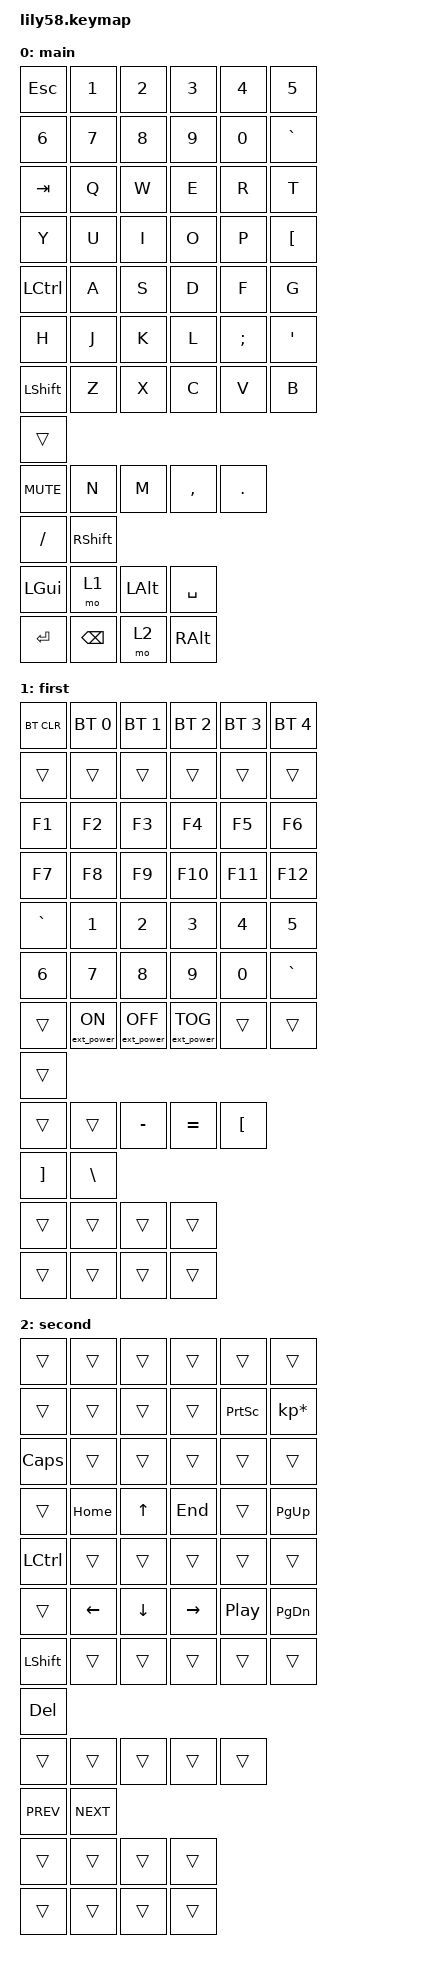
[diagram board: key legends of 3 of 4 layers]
/*
 * Copyright (c) 2020 The ZMK Contributors
 *
 * SPDX-License-Identifier: MIT
 */

#include <behaviors.dtsi>
#include <dt-bindings/zmk/keys.h>
#include <dt-bindings/zmk/bt.h>
#include <dt-bindings/zmk/ext_power.h>
#include <dt-bindings/zmk/rgb.h>

/ {
    conditional_layers {
        compatible = "zmk,conditional-layers";

        adjust_layer {
            if-layers = <1 2>;
            then-layer = <3>;
        };
    };

    keymap {
        compatible = "zmk,keymap";

        /*
         * Layer 0 — твой скрин 0
         */
        default_layer {
			display-name = "main";

            bindings = <
                &kp ESC       &kp N1      &kp N2      &kp N3      &kp N4      &kp N5
                &kp N6        &kp N7      &kp N8      &kp N9      &kp N0      &kp GRAVE

                &kp TAB       &kp Q       &kp W       &kp E       &kp R       &kp T
                &kp Y         &kp U       &kp I       &kp O       &kp P       &kp LBKT

                &kp LCTRL     &kp A       &kp S       &kp D       &kp F       &kp G
                &kp H         &kp J       &kp K       &kp L       &kp SEMI     &kp SQT

                &kp LSHFT     &kp Z       &kp X       &kp C       &kp V       &kp B
                &trans
                &kp C_MUTE    &kp N       &kp M       &kp COMMA    &kp DOT
                &kp FSLH      &kp RSHFT

                &kp LGUI      &mo 1       &kp LALT    &kp SPACE
                &kp RET       &kp BSPC    &mo 2       &kp RALT
            >;

            sensor-bindings = <
                &inc_dec_kp C_VOL_UP C_VOL_DN
                &inc_dec_kp C_VOL_UP C_VOL_DN
            >;
        };

        /*
         * Layer 1 — твой скрин 1
         */
        lower_layer {
			display-name = "first";

            bindings = <
                &bt BT_CLR       &bt BT_SEL 0     &bt BT_SEL 1     &bt BT_SEL 2     &bt BT_SEL 3     &bt BT_SEL 4
                &trans           &trans           &trans           &trans           &trans           &trans

                &kp F1           &kp F2            &kp F3            &kp F4            &kp F5            &kp F6
                &kp F7           &kp F8            &kp F9            &kp F10           &kp F11           &kp F12

                &kp GRAVE        &kp N1            &kp N2            &kp N3            &kp N4            &kp N5
                &kp N6           &kp N7            &kp N8            &kp N9            &kp N0            &kp GRAVE

                &trans           &ext_power EP_ON  &ext_power EP_OFF  &ext_power EP_TOG  &trans           &trans
                &trans           &trans            &trans             &kp MINUS         &kp EQUAL        &kp LBKT
                &kp RBKT         &kp BSLH

                &trans           &trans           &trans           &trans
                &trans           &trans           &trans           &trans
            >;

            sensor-bindings = <
                &inc_dec_kp C_VOL_UP C_VOL_DN
                &inc_dec_kp C_VOL_UP C_VOL_DN
            >;
        };

        /*
         * Layer 2 — твой скрин 3
         */
        raise_layer {
			display-name = "second";

			bindings = <
				&trans        &trans        &trans        &trans        &trans        &trans
				&trans        &trans        &trans        &trans        &kp PSCRN      &kp KP_MULTIPLY

				&kp CAPS      &trans        &trans        &trans        &trans        &trans
				&trans        &kp HOME      &kp UP        &kp END       &trans        &kp PG_UP

				&kp LCTRL     &trans        &trans        &trans        &trans        &trans
				&trans        &kp LEFT      &kp DOWN      &kp RIGHT      &kp C_PP      &kp PG_DN

				&kp LSHFT     &trans        &trans        &trans        &trans        &trans
				&kp DEL       &trans        &trans        &trans        &trans        &trans        &kp C_PREV    &kp C_NEXT

				&trans        &trans        &trans        &trans
				&trans        &trans        &trans        &trans
			>;

			sensor-bindings = <
				&inc_dec_kp C_VOL_UP C_VOL_DN
				&inc_dec_kp C_VOL_UP C_VOL_DN
			>;
		};
		
        /*
         * Layer 3 — ОРИГИНАЛЬНЫЙ ADJUST
         */
        adjust_layer {
			display-name = "adj";

            bindings = <
                &bt BT_CLR        &bt BT_SEL 0    &bt BT_SEL 1    &bt BT_SEL 2    &bt BT_SEL 3    &bt BT_SEL 4
                &trans            &trans          &trans          &trans          &trans          &trans

                &ext_power EP_TOG &rgb_ug RGB_HUD &rgb_ug RGB_HUI &rgb_ug RGB_SAD &rgb_ug RGB_SAI &rgb_ug RGB_EFF
                &trans            &trans          &trans          &trans          &trans          &trans

                &trans            &rgb_ug RGB_BRD &rgb_ug RGB_BRI &trans          &trans          &trans
                &trans            &trans          &trans          &trans          &trans          &trans
                &trans            &trans

                &trans            &trans          &trans          &trans          &trans          &trans
                &trans            &trans          &trans          &trans          &trans          &trans
                &trans            &trans

                &trans            &trans          &trans          &trans
                &trans            &trans          &trans          &trans
            >;

            sensor-bindings = <
                &inc_dec_kp C_VOL_UP C_VOL_DN
                &inc_dec_kp C_VOL_UP C_VOL_DN
            >;
        };

        /*
         * Дополнительные слои для ZMK Studio
         */
        extra1 {
            status = "reserved";
        };

        extra2 {
            status = "reserved";
        };

        extra3 {
            status = "reserved";
        };

        extra4 {
            status = "reserved";
        };

        extra5 {
            status = "reserved";
        };
    };
};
